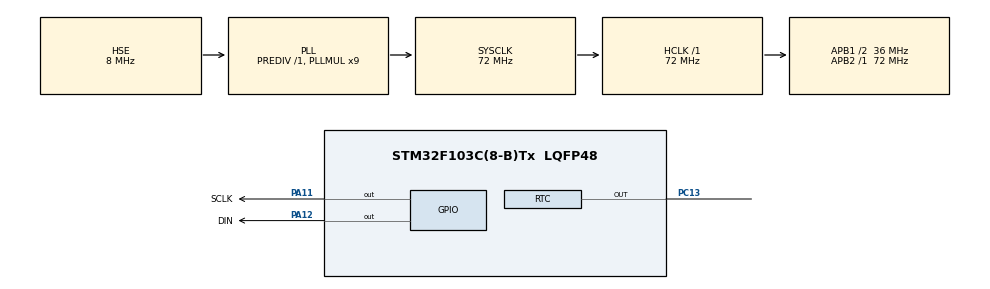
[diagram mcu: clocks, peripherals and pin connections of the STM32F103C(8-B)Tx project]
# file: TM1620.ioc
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Mcu.Family=STM32F1
Mcu.Name=STM32F103C(8-B)Tx
Mcu.Package=LQFP48
NVIC.PriorityGroup=NVIC_PRIORITYGROUP_4
NVIC.RTC_Alarm_IRQn=true\:0\:0\:false\:false\:true\:true\:true\:true
PA11.GPIO_Label=SCLK
PA11.GPIO_Speed=GPIO_SPEED_FREQ_HIGH
PA11.Signal=GPIO_Output
PA12.GPIO_Label=DIN
PA12.GPIO_Speed=GPIO_SPEED_FREQ_HIGH
PA12.Signal=GPIO_Output
PC13-TAMPER-RTC.Mode=RTC OUT
PC13-TAMPER-RTC.Signal=RTC_OUT
PC14-OSC32_IN.Mode=LSE-External-Oscillator
PC14-OSC32_IN.Signal=RCC_OSC32_IN
PC15-OSC32_OUT.Mode=LSE-External-Oscillator
PC15-OSC32_OUT.Signal=RCC_OSC32_OUT
PD0-OSC_IN.Mode=HSE-External-Oscillator
PD0-OSC_IN.Signal=RCC_OSC_IN
PD1-OSC_OUT.Mode=HSE-External-Oscillator
PD1-OSC_OUT.Signal=RCC_OSC_OUT
ProjectManager.HeapSize=0x200
ProjectManager.StackSize=0x400
ProjectManager.TargetToolchain=MDK-ARM V5.32
RCC.AHBFreq_Value=72000000
RCC.APB1CLKDivider=RCC_HCLK_DIV2
RCC.APB1Freq_Value=36000000
RCC.APB1TimFreq_Value=72000000
RCC.APB2Freq_Value=72000000
RCC.APB2TimFreq_Value=72000000
RCC.HCLKFreq_Value=72000000
RCC.PLLMUL=RCC_PLL_MUL9
RCC.PLLSourceVirtual=RCC_PLLSOURCE_HSE
RCC.SYSCLKFreq_VALUE=72000000
RCC.SYSCLKSource=RCC_SYSCLKSOURCE_PLLCLK
RCC.USBFreq_Value=72000000
RTC.Date=12
RTC.Format=RTC_FORMAT_BIN
RTC.Hours=14
RTC.Minutes=50
RTC.Month=RTC_MONTH_JULY
RTC.WeekDay=RTC_WEEKDAY_WEDNESDAY
RTC.Year=23
VP_RTC_VS_RTC_Activate.Mode=RTC_Enabled
VP_RTC_VS_RTC_Calendar.Mode=RTC_Calendar
VP_SYS_VS_ND.Mode=No_Debug
board=custom

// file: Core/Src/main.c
/* USER CODE BEGIN Header */
/**
  ******************************************************************************
  * @file           : main.c
  * @brief          : Main program body
  ******************************************************************************
  * @attention
  *
  * Copyright (c) 2023 STMicroelectronics.
  * All rights reserved.
  *
  * This software is licensed under terms that can be found in the LICENSE file
  * in the root directory of this software component.
  * If no LICENSE file comes with this software, it is provided AS-IS.
  *
  ******************************************************************************
  */
/* USER CODE END Header */
#include "main.h"
#include "rtc.h"
#include "gpio.h"

/* USER CODE BEGIN Includes */
#include "TM1620.h"
/* USER CODE END Includes */

/* USER CODE BEGIN PM */
	RTC_TimeTypeDef time;
	RTC_DateTypeDef date;
/* USER CODE END PM */

void SystemClock_Config(void);

int main(void)
{

  /* MCU Configuration--------------------------------------------------------*/

  /* Reset of all peripherals, Initializes the Flash interface and the Systick. */
  HAL_Init();

  /* Configure the system clock */
  SystemClock_Config();

  /* Initialize all configured peripherals */
  MX_GPIO_Init();
  MX_RTC_Init();
  /* USER CODE BEGIN 2 */
	TM1620_Init();
  /* USER CODE END 2 */

  /* Infinite loop */
  /* USER CODE BEGIN WHILE */
  while (1)
  {
			TM1620_display(0,date.Date/10);	//天
			TM1620_display(1,date.Date%10);
			TM1620_display(2,time.Hours/10); //时
			TM1620_display(3,time.Hours%10);
			TM1620_display(4,time.Minutes/10);	//分
			TM1620_display(5,time.Minutes%10);
			TM1620_display(6,time.Seconds/10); //秒
			TM1620_display(7,time.Seconds%10);
	  HAL_Delay(10);
    /* USER CODE END WHILE */

  }
}

void SystemClock_Config(void)
{
  RCC_OscInitTypeDef RCC_OscInitStruct = {0};
  RCC_ClkInitTypeDef RCC_ClkInitStruct = {0};
  RCC_PeriphCLKInitTypeDef PeriphClkInit = {0};

  /** Initializes the RCC Oscillators according to the specified parameters
  * in the RCC_OscInitTypeDef structure.
  */
  RCC_OscInitStruct.OscillatorType = RCC_OSCILLATORTYPE_LSI|RCC_OSCILLATORTYPE_HSE;
  RCC_OscInitStruct.HSEState = RCC_HSE_ON;
  RCC_OscInitStruct.HSEPredivValue = RCC_HSE_PREDIV_DIV1;
  RCC_OscInitStruct.HSIState = RCC_HSI_ON;
  RCC_OscInitStruct.LSIState = RCC_LSI_ON;
  RCC_OscInitStruct.PLL.PLLState = RCC_PLL_ON;
  RCC_OscInitStruct.PLL.PLLSource = RCC_PLLSOURCE_HSE;
  RCC_OscInitStruct.PLL.PLLMUL = RCC_PLL_MUL9;
  if (HAL_RCC_OscConfig(&RCC_OscInitStruct) != HAL_OK)
  {
    Error_Handler();
  }

  /** Initializes the CPU, AHB and APB buses clocks
  */
  RCC_ClkInitStruct.ClockType = RCC_CLOCKTYPE_HCLK|RCC_CLOCKTYPE_SYSCLK
                              |RCC_CLOCKTYPE_PCLK1|RCC_CLOCKTYPE_PCLK2;
  RCC_ClkInitStruct.SYSCLKSource = RCC_SYSCLKSOURCE_PLLCLK;
  RCC_ClkInitStruct.AHBCLKDivider = RCC_SYSCLK_DIV1;
  RCC_ClkInitStruct.APB1CLKDivider = RCC_HCLK_DIV2;
  RCC_ClkInitStruct.APB2CLKDivider = RCC_HCLK_DIV1;

  if (HAL_RCC_ClockConfig(&RCC_ClkInitStruct, FLASH_LATENCY_2) != HAL_OK)
  {
    Error_Handler();
  }
  PeriphClkInit.PeriphClockSelection = RCC_PERIPHCLK_RTC;
  PeriphClkInit.RTCClockSelection = RCC_RTCCLKSOURCE_LSI;
  if (HAL_RCCEx_PeriphCLKConfig(&PeriphClkInit) != HAL_OK)
  {
    Error_Handler();
  }
}

void Error_Handler(void)
{
  __disable_irq();
  while (1)
  {
  }
}
